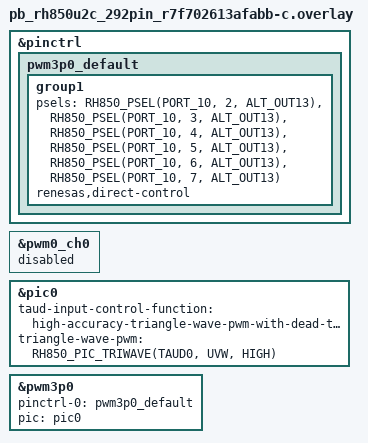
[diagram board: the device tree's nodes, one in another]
/*
 * Copyright (c) 2026 Renesas Electronics Corporation
 * SPDX-License-Identifier: Apache-2.0
 */

#include <zephyr/dt-bindings/pic/renesas/pic-rh850-common.h>
#include <dt-bindings/pinctrl/renesas/pinctrl-rh850u2c.h>

&pinctrl {
	pwm3p0_default: pwm3p0_default {
		group1 {
			psels = <RH850_PSEL(PORT_10, 2, ALT_OUT13)>,  /* U high */
				<RH850_PSEL(PORT_10, 3, ALT_OUT13)>,  /* U low  */
				<RH850_PSEL(PORT_10, 4, ALT_OUT13)>,  /* V high */
				<RH850_PSEL(PORT_10, 5, ALT_OUT13)>,  /* V low  */
				<RH850_PSEL(PORT_10, 6, ALT_OUT13)>,  /* W high */
				<RH850_PSEL(PORT_10, 7, ALT_OUT13)>;  /* W low  */
			renesas,direct-control;
		};
	};
};

/*
 * Opt-in: enable the PIC and PWM3P nodes, they are disabled at board level. The PWM3P master
 * channel is the same timer channel used by pwm0_ch2, so disable the pwm0_ch0 group so that it
 * does not conflict with PWM3P.
 */
&pwm0_ch0 {
	status = "disabled";
};

&pic0 {
	taud-input-control-function = "high-accuracy-triangle-wave-pwm-with-dead-time";
	triangle-wave-pwm = <RH850_PIC_TRIWAVE(TAUD0, UVW, HIGH)>;
	status = "okay";
};

&pwm3p0 {
	pinctrl-0 = <&pwm3p0_default>;
	pinctrl-names = "default";
	pic = <&pic0>;
	status = "okay";
};
